# ATxmega128A1 register map
Vendor: Atmel; File version: 1.0
CPU: other r0p0, little endian, no MPU, no FPU, 4 interrupt priority bits
Registers are 8-bit, read-write, reset 0x0 unless marked. A register's access mark holds for its fields unless they carry their own. Offsets are from the block's base; [hi:lo] are bit positions; lines under a group give offsets from that group; {n}, {i} and the like mark numbered series; 'fields as' and 'values as' point back to an identical list.

## RST — Reset
Base 0x00000078
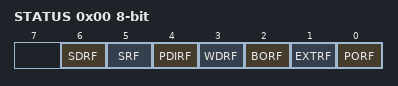
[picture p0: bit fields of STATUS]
0x00 STATUS
  [6] SDRF — Spike Detection Reset Flag
  [5] SRF — Software Reset Flag
  [4] PDIRF — Programming and Debug Interface Interface Reset Flag
  [3] WDRF — Watchdog Reset Flag
  [2] BORF — Brown-out Reset Flag
  [1] EXTRF — External Reset Flag
  [0] PORF — Power-on Reset Flag
0x01 CTRL — Control Register
  [0] SWRST — Software Reset

## RTC — Real-Time Counter
Base 0x00000400
0x00 CTRL — Control Register
  [2:0] PRESCALER — Prescaling Factor
    0=OFF (RTC Off); 1=DIV1 (RTC Clock); 2=DIV2 (RTC Clock / 2); 3=DIV8 (RTC Clock / 8); 4=DIV16 (RTC Clock / 16); 5=DIV64 (RTC Clock / 64); 6=DIV256 (RTC Clock / 256); 7=DIV1024 (RTC Clock / 1024)
0x01 STATUS
  [0] SYNCBUSY — Synchronization Busy Flag
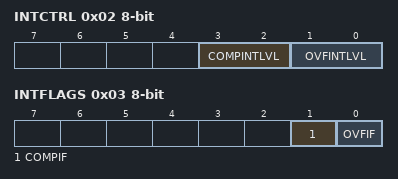
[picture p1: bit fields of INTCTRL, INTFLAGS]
0x02 INTCTRL — Interrupt Control Register
  [3:2] COMPINTLVL — Compare Match Interrupt Level
    0=OFF (Interrupt Disabled); 1=LO (Low Level); 2=MED (Medium Level); 3=HI (High Level)
  [1:0] OVFINTLVL — Overflow Interrupt Level
    values as COMPINTLVL
0x03 INTFLAGS — Interrupt Flags
  [1] COMPIF — Compare Match Interrupt Flag
  [0] OVFIF — Overflow Interrupt Flag
0x04 TEMP — Temporary register
0x08 CNT 16-bit (reset mask 0xFF) — Count Register
0x0A PER 16-bit (reset mask 0xFF) — Period Register
0x0C COMP 16-bit (reset mask 0xFF) — Compare Register

## SLEEP — Sleep Controller
Base 0x00000048
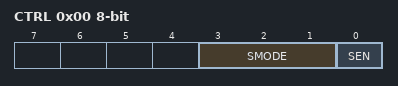
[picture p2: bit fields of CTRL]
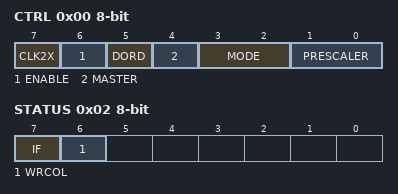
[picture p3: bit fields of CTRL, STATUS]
0x00 CTRL — Control Register
  [3:1] SMODE — Sleep Mode
    0=IDLE (Idle mode); 2=PDOWN (Power-down Mode); 3=PSAVE (Power-save Mode); 6=STDBY (Standby Mode); 7=ESTDBY (Extended Standby Mode)
  [0] SEN — Sleep Enable

## SPIC — Serial Peripheral Interface
Base 0x000008C0
Same registers: SPID 0x000009C0, SPIE 0x00000AC0, SPIF 0x00000BC0
0x00 CTRL — Control Register
  [7] CLK2X — Enable Double Speed
  [6] ENABLE — Enable Module
  [5] DORD — Data Order Setting
  [4] MASTER — Master Operation Enable
  [3:2] MODE — SPI Mode
    {v}=SPI Mode {v} (v=0..3)
  [1:0] PRESCALER
    0=DIV4 (System Clock / 4); 1=DIV16 (System Clock / 16); 2=DIV64 (System Clock / 64); 3=DIV128 (System Clock / 128)
0x01 INTCTRL — Interrupt Control Register
  [1:0] INTLVL — Interrupt level
    0=OFF (Interrupt Disabled); 1=LO (Low Level); 2=MED (Medium Level); 3=HI (High Level)
0x02 STATUS
  [7] IF — Interrupt Flag
  [6] WRCOL — Write Collision
0x03 DATA

## TWIC — Two-Wire Interface
Base 0x00000480
Same registers: TWID 0x00000490, TWIE 0x000004A0, TWIF 0x000004B0
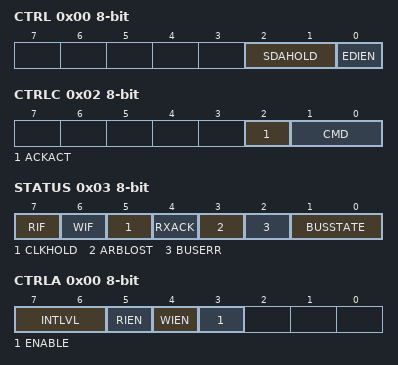
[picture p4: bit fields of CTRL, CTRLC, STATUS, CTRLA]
0x00 CTRL — TWI Common Control Register
  [2:1] SDAHOLD — SDA Hold Time Enable
    0=OFF (SDA hold time off); 1=50NS (Typical 50ns hold time); 2=300NS (Typical 300ns hold time); 3=400NS (Typical 400ns hold time)
  [0] EDIEN — External Driver Interface Enable
0x00 MASTER group
  0x00 CTRLA — Control Register A
    [7:6] INTLVL — Interrupt Level
      0=OFF (Interrupt Disabled); 1=LO (Low Level); 2=MED (Medium Level); 3=HI (High Level)
    [5] RIEN — Read Interrupt Enable
    [4] WIEN — Write Interrupt Enable
    [3] ENABLE — Enable TWI Master
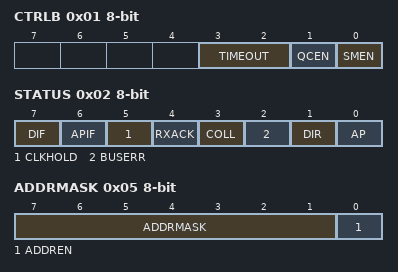
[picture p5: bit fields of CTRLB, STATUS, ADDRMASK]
  0x01 CTRLB — Control Register B
    [3:2] TIMEOUT — Inactive Bus timeout
      0=DISABLED (Bus Timeout Disabled); 1=50US (50 Microseconds); 2=100US (100 Microseconds); 3=200US (200 Microseconds)
    [1] QCEN — Quick Command Enable
    [0] SMEN — Smart Mode Enable
  0x02 CTRLC — Control Register C
    [2] ACKACT — Acknowledge Action
    [1:0] CMD — Command
      0=NOACT (No Action); 1=REPSTART (Issue Repeated Start Condition); 2=RECVTRANS (Receive or Transmit Data); 3=STOP (Issue Stop Condition)
  0x03 STATUS
    [7] RIF — Read Interrupt Flag
    [6] WIF — Write Interrupt Flag
    [5] CLKHOLD — Clock Hold
    [4] RXACK — Received Acknowledge
    [3] ARBLOST — Arbitration Lost
    [2] BUSERR — Bus Error
    [1:0] BUSSTATE
      0=UNKNOWN (Unknown Bus State); 1=IDLE (Bus is Idle); 2=OWNER (This Module Controls The Bus); 3=BUSY (The Bus is Busy)
  0x04 BAUD — Baud Rate Control Register
  0x05 ADDR — Address Register
  0x06 DATA
0x00 SLAVE group
  0x00 CTRLA — Control Register A
    [7:6] INTLVL — Interrupt Level
      values as MASTER.CTRLA.INTLVL
    [5] DIEN — Data Interrupt Enable
    [4] APIEN — Address/Stop Interrupt Enable
    [3] ENABLE — Enable TWI Slave
    [2] PIEN — Stop Interrupt Enable
    [1] PMEN — Promiscuous Mode Enable
    [0] SMEN — Smart Mode Enable
  0x01 CTRLB — Control Register B
    [2] ACKACT — Acknowledge Action
    [1:0] CMD — Command
      0=NOACT (No Action); 2=COMPTRANS (Used To Complete a Transaction); 3=RESPONSE (Used in Response to Address/Data Interrupt)
  0x02 STATUS
    [7] DIF — Data Interrupt Flag
    [6] APIF — Address/Stop Interrupt Flag
    [5] CLKHOLD — Clock Hold
    [4] RXACK — Received Acknowledge
    [3] COLL — Collision
    [2] BUSERR — Bus Error
    [1] DIR — Read/Write Direction
    [0] AP — Slave Address or Stop
  0x03 ADDR — Address Register
  0x04 DATA
  0x05 ADDRMASK — Address Mask Register
    [7:1] ADDRMASK — Address Mask
    [0] ADDREN — Address Enable

## USARTC0 — Universal Asynchronous Receiver-Transmitter
Base 0x000008A0
Same registers: USARTC1 0x000008B0, USARTD0 0x000009A0, USARTD1 0x000009B0, USARTE0 0x00000AA0, USARTE1 0x00000AB0, USARTF0 0x00000BA0, USARTF1 0x00000BB0
0x00 DATA
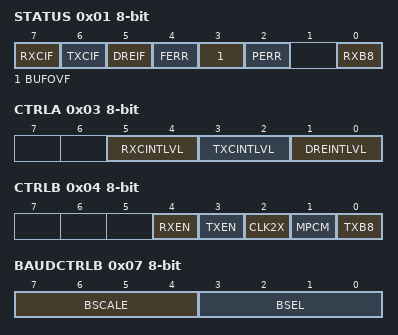
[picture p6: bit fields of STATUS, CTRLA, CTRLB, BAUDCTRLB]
0x01 STATUS
  [7] RXCIF — Receive Interrupt Flag
  [6] TXCIF — Transmit Interrupt Flag
  [5] DREIF — Data Register Empty Flag
  [4] FERR — Frame Error
  [3] BUFOVF — Buffer Overflow
  [2] PERR — Parity Error
  [0] RXB8 — Receive Bit 8
0x03 CTRLA — Control Register A
  [all] fields
    0=OFF (Interrupt Disabled); 1=LO (Low Level); 2=MED (Medium Level); 3=HI (High Level)
  [5:4] RXCINTLVL — Receive Interrupt Level
  [3:2] TXCINTLVL — Transmit Interrupt Level
  [1:0] DREINTLVL — Data Register Empty Interrupt Level
0x04 CTRLB — Control Register B
  [4] RXEN — Receiver Enable
  [3] TXEN — Transmitter Enable
  [2] CLK2X — Double transmission speed
  [1] MPCM — Multi-processor Communication Mode
  [0] TXB8 — Transmit bit 8
0x05 CTRLC — Control Register C
  [7:6] CMODE — Communication Mode
    0=ASYNCHRONOUS (Asynchronous Mode); 1=SYNCHRONOUS (Synchronous Mode); 2=IRDA (IrDA Mode); 3=MSPI (Master SPI Mode)
  [5:4] PMODE — Parity Mode
    0=DISABLED (No Parity); 2=EVEN (Even Parity); 3=ODD (Odd Parity)
  [3] SBMODE — Stop Bit Mode
  [2] UDORD — SPI Master Mode, Data Order
  [1] UCPHA — SPI Master Mode, Clock Phase
  [2:0] CHSIZE — Character Size
    {v}={v+5}BIT (Character size: {v+5} bit) (v=0..3); 7=9BIT (Character size: 9 bit)
0x06 BAUDCTRLA — Baud Rate Control Register A
  [7:0] BSEL — Baud Rate Selection Bits [7:0]
0x07 BAUDCTRLB — Baud Rate Control Register B
  [7:4] BSCALE — Baud Rate Scale
  [3:0] BSEL — Baud Rate Selection bits[11:8]

## VPORT0 — Port Configuration
Base 0x00000010
Same registers: VPORT1 0x00000014, VPORT2 0x00000018, VPORT3 0x0000001C
0x00 DIR — I/O Port Data Direction
0x01 OUT — I/O Port Output
0x02 IN — I/O Port Input
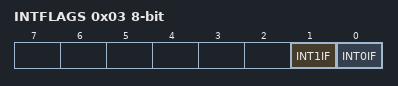
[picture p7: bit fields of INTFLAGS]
0x03 INTFLAGS — Interrupt Flag Register
  [1] INT1IF — Port Interrupt 1 Flag
  [0] INT0IF — Port Interrupt 0 Flag

## WDT — Watch-Dog Timer
Base 0x00000080
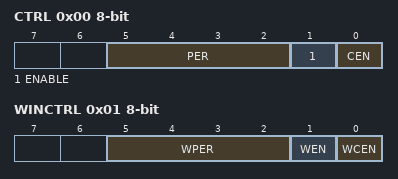
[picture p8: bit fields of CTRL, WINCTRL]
0x00 CTRL — Control
  [5:2] PER — Period
    0=8CLK (8 cycles (8ms @ 3.3V)); 1=16CLK (16 cycles (16ms @ 3.3V)); 2=32CLK (32 cycles (32ms @ 3.3V)); 3=64CLK (64 cycles (64ms @ 3.3V)); 4=128CLK (128 cycles (0.128s @ 3.3V)); 5=256CLK (256 cycles (0.256s @ 3.3V)); 6=512CLK (512 cycles (0.512s @ 3.3V)); 7=1KCLK (1K cycles (1s @ 3.3V)); 8=2KCLK (2K cycles (2s @ 3.3V)); 9=4KCLK (4K cycles (4s @ 3.3V)); 10=8KCLK (8K cycles (8s @ 3.3V))
  [1] ENABLE
  [0] CEN — Change Enable
0x01 WINCTRL — Windowed Mode Control
  [5:2] WPER — Windowed Mode Period
    values as CTRL.PER
  [1] WEN — Windowed Mode Enable
  [0] WCEN — Windowed Mode Change Enable
0x02 STATUS
  [0] SYNCBUSY — Syncronization busy
